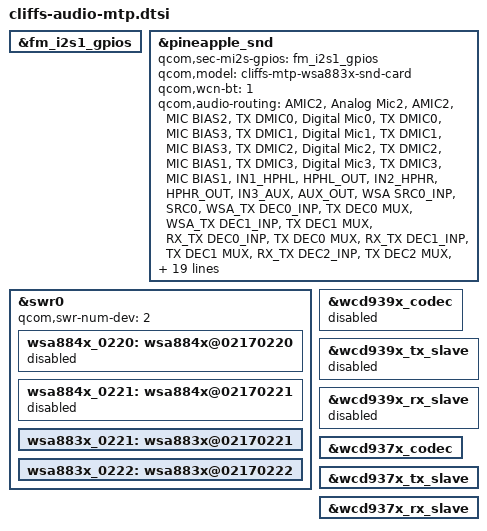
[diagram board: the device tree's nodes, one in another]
#include "cliffs-audio-overlay.dtsi"

&fm_i2s1_gpios {
	status = "ok";
};

&pineapple_snd {
	qcom,sec-mi2s-gpios = <&fm_i2s1_gpios>;
	qcom,model = "cliffs-mtp-wsa883x-snd-card";
	qcom,wcn-bt = <1>;
	qcom,audio-routing =
		"AMIC2", "Analog Mic2",
		"AMIC2", "MIC BIAS2",
		"TX DMIC0", "Digital Mic0",
		"TX DMIC0", "MIC BIAS3",
		"TX DMIC1", "Digital Mic1",
		"TX DMIC1", "MIC BIAS3",
		"TX DMIC2", "Digital Mic2",
		"TX DMIC2", "MIC BIAS1",
		"TX DMIC3", "Digital Mic3",
		"TX DMIC3", "MIC BIAS1",
		"IN1_HPHL", "HPHL_OUT",
		"IN2_HPHR", "HPHR_OUT",
		"IN3_AUX", "AUX_OUT",
		"WSA SRC0_INP", "SRC0",
		"WSA_TX DEC0_INP", "TX DEC0 MUX",
		"WSA_TX DEC1_INP", "TX DEC1 MUX",
		"RX_TX DEC0_INP", "TX DEC0 MUX",
		"RX_TX DEC1_INP", "TX DEC1 MUX",
		"RX_TX DEC2_INP", "TX DEC2 MUX",
		"RX_TX DEC3_INP", "TX DEC3 MUX",
		"SpkrLeft IN", "WSA_SPK1 OUT",
		"SpkrRight IN", "WSA_SPK2 OUT",
		"TX SWR_INPUT", "WCD_TX_OUTPUT",
		"VA SWR_INPUT", "VA_SWR_CLK",
		"VA SWR_INPUT", "WCD_TX_OUTPUT",
		"VA_AIF1 CAP", "VA_SWR_CLK",
		"VA_AIF2 CAP", "VA_SWR_CLK",
		"VA_AIF3 CAP", "VA_SWR_CLK",
		"VA DMIC0", "Digital Mic0",
		"VA DMIC1", "Digital Mic1",
		"VA DMIC2", "Digital Mic2",
		"VA DMIC3", "Digital Mic3",
		"VA DMIC0", "VA MIC BIAS3",
		"VA DMIC1", "VA MIC BIAS3",
		"VA DMIC2", "VA MIC BIAS1",
		"VA DMIC3", "VA MIC BIAS1";
		qcom,msm-mbhc-usbc-audio-supported = <0>;
		qcom,msm-mbhc-hphl-swh = <1>;
		qcom,msm-mbhc-gnd-swh = <1>;
		asoc-codec  = <&stub_codec>, <&lpass_cdc>,
			      <&wcd937x_codec>, <&wsa883x_0221>,
			      <&wsa883x_0222>;
		asoc-codec-names = "msm-stub-codec.1", "lpass-cdc",
				   "wcd937x_codec", "wsa-codec1",
				   "wsa-codec2";
};

&swr0 {
	qcom,swr-num-dev = <2>;

	wsa884x_0220: wsa884x@02170220 {
		status = "disabled";
	};

	wsa884x_0221: wsa884x@02170221 {
		status = "disabled";
	};

	wsa883x_0221: wsa883x@02170221 {
		status = "okay";
	};

	wsa883x_0222: wsa883x@02170222 {
		status = "okay";
	};
};

&wcd939x_codec {
	status = "disabled";
};

&wcd939x_tx_slave {
	status = "disabled";
};

&wcd939x_rx_slave {
	status = "disabled";
};

&wcd937x_codec {
	status = "okay";
};

&wcd937x_tx_slave {
	status = "okay";
};

&wcd937x_rx_slave {
	status = "okay";
};
